# TM4C129ENCPDT register map
File version: 1.0
CPU: CORTEX_M4 1.0, other endian, MPU, FPU, 3 interrupt priority bits
Registers are 32-bit, read-write, reset 0x0 unless marked. A register's access mark holds for its fields unless they carry their own. Offsets are from the block's base; [hi:lo] are bit positions.

## CAN0 — CAN register offsets
Base 0x40040000
Same registers: CAN1 0x40041000
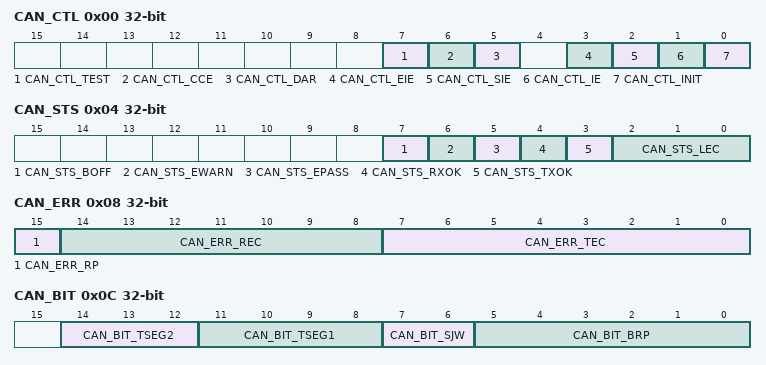
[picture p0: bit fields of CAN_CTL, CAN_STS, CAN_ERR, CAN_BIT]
0x00 CAN_CTL — CAN Control
  [7] CAN_CTL_TEST — [7:7] Test Mode Enable
  [6] CAN_CTL_CCE — [6:6] Configuration Change Enable
  [5] CAN_CTL_DAR — [5:5] Disable Automatic-Retransmission
  [3] CAN_CTL_EIE — [3:3] Error Interrupt Enable
  [2] CAN_CTL_SIE — [2:2] Status Interrupt Enable
  [1] CAN_CTL_IE — [1:1] CAN Interrupt Enable
  [0] CAN_CTL_INIT — [0:0] Initialization
0x04 CAN_STS — CAN Status
  [7] CAN_STS_BOFF — [7:7] Bus-Off Status
  [6] CAN_STS_EWARN — [6:6] Warning Status
  [5] CAN_STS_EPASS — [5:5] Error Passive
  [4] CAN_STS_RXOK — [4:4] Received a Message Successfully
  [3] CAN_STS_TXOK — [3:3] Transmitted a Message Successfully
  [2:0] CAN_STS_LEC — [2:0] Last Error Code
    0=CAN_STS_LEC_NONE (No Error); 1=CAN_STS_LEC_STUFF (Stuff Error); 2=CAN_STS_LEC_FORM (Format Error); 3=CAN_STS_LEC_ACK (ACK Error); 4=CAN_STS_LEC_BIT1 (Bit 1 Error); 5=CAN_STS_LEC_BIT0 (Bit 0 Error); 6=CAN_STS_LEC_CRC (CRC Error); 7=CAN_STS_LEC_NOEVENT (No Event)
0x08 CAN_ERR — CAN Error Counter
  [15] CAN_ERR_RP — [15:15] Received Error Passive
  [14:8] CAN_ERR_REC — [14:8] Receive Error Counter
  [7:0] CAN_ERR_TEC — [7:0] Transmit Error Counter
0x0C CAN_BIT — CAN Bit Timing
  [14:12] CAN_BIT_TSEG2 — [14:12] Time Segment after Sample Point
  [11:8] CAN_BIT_TSEG1 — [11:8] Time Segment Before Sample Point
  [7:6] CAN_BIT_SJW — [7:6] (Re)Synchronization Jump Width
  [5:0] CAN_BIT_BRP — [5:0] Baud Rate Prescaler
0x10 CAN_INT — CAN Interrupt
  [15:0] CAN_INT_INTID — [15:0] Interrupt Identifier
    0=CAN_INT_INTID_NONE (No interrupt pending); 0x8000=CAN_INT_INTID_STATUS (Status Interrupt)
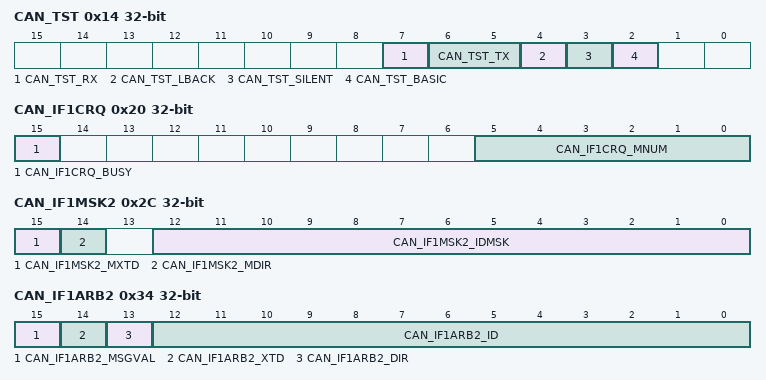
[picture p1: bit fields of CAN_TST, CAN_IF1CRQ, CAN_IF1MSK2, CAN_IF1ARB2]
0x14 CAN_TST — CAN Test
  [7] CAN_TST_RX — [7:7] Receive Observation
  [6:5] CAN_TST_TX — [6:5] Transmit Control
    0=CAN_TST_TX_CANCTL (CAN Module Control); 32=CAN_TST_TX_SAMPLE (Sample Point); 64=CAN_TST_TX_DOMINANT (Driven Low); 96=CAN_TST_TX_RECESSIVE (Driven High)
  [4] CAN_TST_LBACK — [4:4] Loopback Mode
  [3] CAN_TST_SILENT — [3:3] Silent Mode
  [2] CAN_TST_BASIC — [2:2] Basic Mode
0x18 CAN_BRPE — CAN Baud Rate Prescaler Extension
  [3:0] CAN_BRPE_BRPE — [3:0] Baud Rate Prescaler Extension
0x20 CAN_IF1CRQ — CAN IF1 Command Request
  [15] CAN_IF1CRQ_BUSY — [15:15] Busy Flag
  [5:0] CAN_IF1CRQ_MNUM — [5:0] Message Number
0x24 CAN_IF1CMSK — CAN IF1 Command Mask
  [7] CAN_IF1CMSK_WRNRD — [7:7] Write, Not Read
  [6] CAN_IF1CMSK_MASK — [6:6] Access Mask Bits
  [5] CAN_IF1CMSK_ARB — [5:5] Access Arbitration Bits
  [4] CAN_IF1CMSK_CONTROL — [4:4] Access Control Bits
  [3] CAN_IF1CMSK_CLRINTPND — [3:3] Clear Interrupt Pending Bit
  [2] CAN_IF1CMSK_NEWDAT — [2:2] Access New Data
  [2] CAN_IF1CMSK_TXRQST — [2:2] Access Transmission Request
  [1] CAN_IF1CMSK_DATAA — [1:1] Access Data Byte 0 to 3
  [0] CAN_IF1CMSK_DATAB — [0:0] Access Data Byte 4 to 7
0x28 CAN_IF1MSK1 — CAN IF1 Mask 1
  [15:0] CAN_IF1MSK1_IDMSK — [15:0] Identifier Mask
0x2C CAN_IF1MSK2 — CAN IF1 Mask 2
  [15] CAN_IF1MSK2_MXTD — [15:15] Mask Extended Identifier
  [14] CAN_IF1MSK2_MDIR — [14:14] Mask Message Direction
  [12:0] CAN_IF1MSK2_IDMSK — [12:0] Identifier Mask
0x30 CAN_IF1ARB1 — CAN IF1 Arbitration 1
  [15:0] CAN_IF1ARB1_ID — [15:0] Message Identifier
0x34 CAN_IF1ARB2 — CAN IF1 Arbitration 2
  [15] CAN_IF1ARB2_MSGVAL — [15:15] Message Valid
  [14] CAN_IF1ARB2_XTD — [14:14] Extended Identifier
  [13] CAN_IF1ARB2_DIR — [13:13] Message Direction
  [12:0] CAN_IF1ARB2_ID — [12:0] Message Identifier
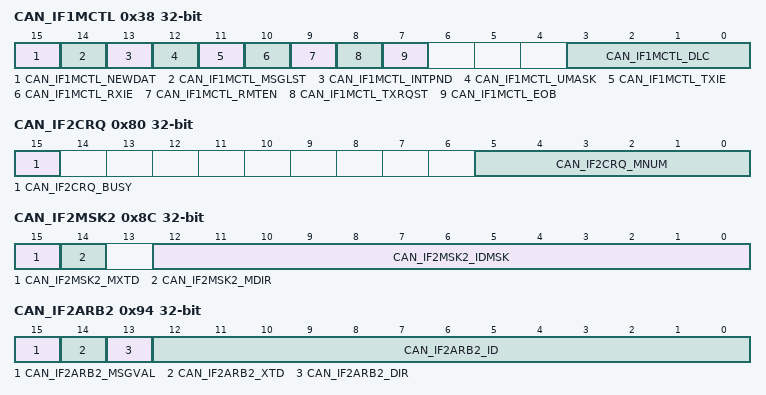
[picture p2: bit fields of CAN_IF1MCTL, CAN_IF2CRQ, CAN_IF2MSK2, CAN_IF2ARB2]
0x38 CAN_IF1MCTL — CAN IF1 Message Control
  [15] CAN_IF1MCTL_NEWDAT — [15:15] New Data
  [14] CAN_IF1MCTL_MSGLST — [14:14] Message Lost
  [13] CAN_IF1MCTL_INTPND — [13:13] Interrupt Pending
  [12] CAN_IF1MCTL_UMASK — [12:12] Use Acceptance Mask
  [11] CAN_IF1MCTL_TXIE — [11:11] Transmit Interrupt Enable
  [10] CAN_IF1MCTL_RXIE — [10:10] Receive Interrupt Enable
  [9] CAN_IF1MCTL_RMTEN — [9:9] Remote Enable
  [8] CAN_IF1MCTL_TXRQST — [8:8] Transmit Request
  [7] CAN_IF1MCTL_EOB — [7:7] End of Buffer
  [3:0] CAN_IF1MCTL_DLC — [3:0] Data Length Code
0x3C CAN_IF1DA1 — CAN IF1 Data A1
  [15:0] CAN_IF1DA1_DATA — [15:0] Data
0x40 CAN_IF1DA2 — CAN IF1 Data A2
  [15:0] CAN_IF1DA2_DATA — [15:0] Data
0x44 CAN_IF1DB1 — CAN IF1 Data B1
  [15:0] CAN_IF1DB1_DATA — [15:0] Data
0x48 CAN_IF1DB2 — CAN IF1 Data B2
  [15:0] CAN_IF1DB2_DATA — [15:0] Data
0x80 CAN_IF2CRQ — CAN IF2 Command Request
  [15] CAN_IF2CRQ_BUSY — [15:15] Busy Flag
  [5:0] CAN_IF2CRQ_MNUM — [5:0] Message Number
0x84 CAN_IF2CMSK — CAN IF2 Command Mask
  [7] CAN_IF2CMSK_WRNRD — [7:7] Write, Not Read
  [6] CAN_IF2CMSK_MASK — [6:6] Access Mask Bits
  [5] CAN_IF2CMSK_ARB — [5:5] Access Arbitration Bits
  [4] CAN_IF2CMSK_CONTROL — [4:4] Access Control Bits
  [3] CAN_IF2CMSK_CLRINTPND — [3:3] Clear Interrupt Pending Bit
  [2] CAN_IF2CMSK_NEWDAT — [2:2] Access New Data
  [2] CAN_IF2CMSK_TXRQST — [2:2] Access Transmission Request
  [1] CAN_IF2CMSK_DATAA — [1:1] Access Data Byte 0 to 3
  [0] CAN_IF2CMSK_DATAB — [0:0] Access Data Byte 4 to 7
0x88 CAN_IF2MSK1 — CAN IF2 Mask 1
  [15:0] CAN_IF2MSK1_IDMSK — [15:0] Identifier Mask
0x8C CAN_IF2MSK2 — CAN IF2 Mask 2
  [15] CAN_IF2MSK2_MXTD — [15:15] Mask Extended Identifier
  [14] CAN_IF2MSK2_MDIR — [14:14] Mask Message Direction
  [12:0] CAN_IF2MSK2_IDMSK — [12:0] Identifier Mask
0x90 CAN_IF2ARB1 — CAN IF2 Arbitration 1
  [15:0] CAN_IF2ARB1_ID — [15:0] Message Identifier
0x94 CAN_IF2ARB2 — CAN IF2 Arbitration 2
  [15] CAN_IF2ARB2_MSGVAL — [15:15] Message Valid
  [14] CAN_IF2ARB2_XTD — [14:14] Extended Identifier
  [13] CAN_IF2ARB2_DIR — [13:13] Message Direction
  [12:0] CAN_IF2ARB2_ID — [12:0] Message Identifier
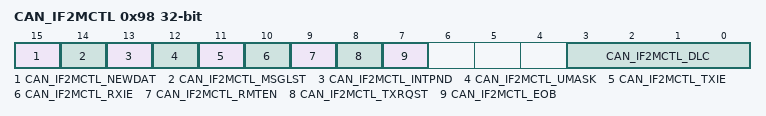
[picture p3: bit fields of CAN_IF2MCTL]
0x98 CAN_IF2MCTL — CAN IF2 Message Control
  [15] CAN_IF2MCTL_NEWDAT — [15:15] New Data
  [14] CAN_IF2MCTL_MSGLST — [14:14] Message Lost
  [13] CAN_IF2MCTL_INTPND — [13:13] Interrupt Pending
  [12] CAN_IF2MCTL_UMASK — [12:12] Use Acceptance Mask
  [11] CAN_IF2MCTL_TXIE — [11:11] Transmit Interrupt Enable
  [10] CAN_IF2MCTL_RXIE — [10:10] Receive Interrupt Enable
  [9] CAN_IF2MCTL_RMTEN — [9:9] Remote Enable
  [8] CAN_IF2MCTL_TXRQST — [8:8] Transmit Request
  [7] CAN_IF2MCTL_EOB — [7:7] End of Buffer
  [3:0] CAN_IF2MCTL_DLC — [3:0] Data Length Code
0x9C CAN_IF2DA1 — CAN IF2 Data A1
  [15:0] CAN_IF2DA1_DATA — [15:0] Data
0xA0 CAN_IF2DA2 — CAN IF2 Data A2
  [15:0] CAN_IF2DA2_DATA — [15:0] Data
0xA4 CAN_IF2DB1 — CAN IF2 Data B1
  [15:0] CAN_IF2DB1_DATA — [15:0] Data
0xA8 CAN_IF2DB2 — CAN IF2 Data B2
  [15:0] CAN_IF2DB2_DATA — [15:0] Data
0x100 CAN_TXRQ1 — CAN Transmission Request 1
  [15:0] CAN_TXRQ1_TXRQST — [15:0] Transmission Request Bits
0x104 CAN_TXRQ2 — CAN Transmission Request 2
  [15:0] CAN_TXRQ2_TXRQST — [15:0] Transmission Request Bits
0x120 CAN_NWDA1 — CAN New Data 1
  [15:0] CAN_NWDA1_NEWDAT — [15:0] New Data Bits
0x124 CAN_NWDA2 — CAN New Data 2
  [15:0] CAN_NWDA2_NEWDAT — [15:0] New Data Bits
0x140 CAN_MSG1INT — CAN Message 1 Interrupt Pending
  [15:0] CAN_MSG1INT_INTPND — [15:0] Interrupt Pending Bits
0x144 CAN_MSG2INT — CAN Message 2 Interrupt Pending
  [15:0] CAN_MSG2INT_INTPND — [15:0] Interrupt Pending Bits
0x160 CAN_MSG1VAL — CAN Message 1 Valid
  [15:0] CAN_MSG1VAL_MSGVAL — [15:0] Message Valid Bits
0x164 CAN_MSG2VAL — CAN Message 2 Valid
  [15:0] CAN_MSG2VAL_MSGVAL — [15:0] Message Valid Bits
